# G32R502 register map
Vendor: Geehy Semiconductor Co., Ltd.; Series: G32R5; File version: 1.0
CPU: CM52 r0p1, little endian, MPU, FPU, DSP, VTOR, 4 interrupt priority bits
Registers are 32-bit, read-write, reset 0x0 unless marked. A register's access mark holds for its fields unless they carry their own. Offsets are from the block's base; [hi:lo] are bit positions; {n}, {i} and the like mark numbered series.

## ROM_PREFETCH
Base 0x40013C00
0x00 BOOT_ROM_PREFETCH
  [0] BOOT_ROM_PREFETCH — BOOT ROM prefetch function enable

## ROM_WAIT_STATE
Base 0x40013D00
0x00 BOOT_ROM_LATENCY reset 0x1 — BOOT ROM delay configuration register
  [2:0] BOOT_ROM_LATENCY — BOOT ROM delay configuration

## DEV — DEV_REGS
Base 0x40013100
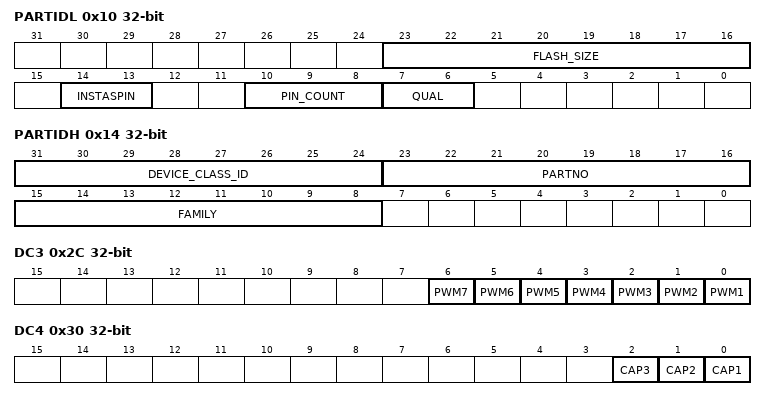
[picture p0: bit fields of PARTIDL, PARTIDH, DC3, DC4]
0x10 PARTIDL ro — Lower 32-bit of Device PART Identification Numble
  [23:16] FLASH_SIZE — Flash size in KB
  [14:13] INSTASPIN — Instaspin feature set
  [10:8] PIN_COUNT — Device Pin Count
  [7:6] QUAL — Qualification Status
0x14 PARTIDH ro — Upper 32-bit of Device PART Identification Numble
  [31:24] DEVICE_CLASS_ID
  [23:16] PARTNO — Device part number
  [15:8] FAMILY — Device family
0x18 REVID ro — Device Revision Number
  [15:0] REVID — Device Revision
0x2C DC3 ro — Device Capability Register
  [n-1] PWM{n} (n=1..7) — PWM{n} function
0x30 DC4 ro — Device Capability Register
  [2] CAP3 — CAP3 function
  [1] CAP2 — CAP2 function
  [0] CAP1 — CAP1 function
0x34 DC5 ro — Device Capability Register
  [0] QEP1 — QEP1 function
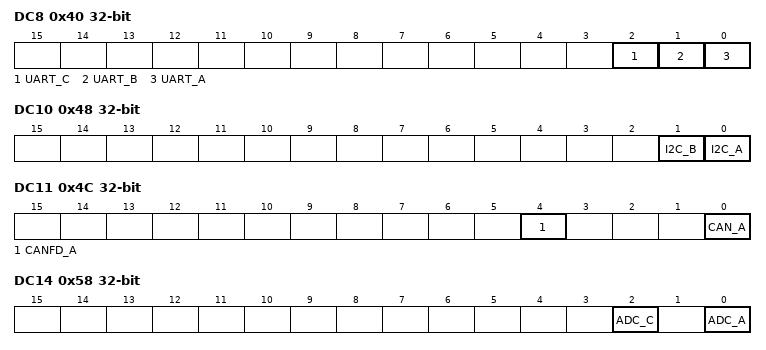
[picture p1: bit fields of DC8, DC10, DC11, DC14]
0x40 DC8 ro — Device Capability Register
  [2] UART_C — UARTC function
  [1] UART_B — UARTB function
  [0] UART_A — UARTA function
0x44 DC9 ro — Device Capability Register
  [0] SPI_A — SPIA function
0x48 DC10 ro — Device Capability Register
  [1] I2C_B — I2CB function
  [0] I2C_A — I2CA function
0x4C DC11 ro — Device Capability Register
  [4] CANFD_A — CANFDA function
  [0] CAN_A — CANA function
0x58 DC14 ro — Device Capability Register
  [2] ADC_C — ADCC function
  [0] ADC_A — ADCA function
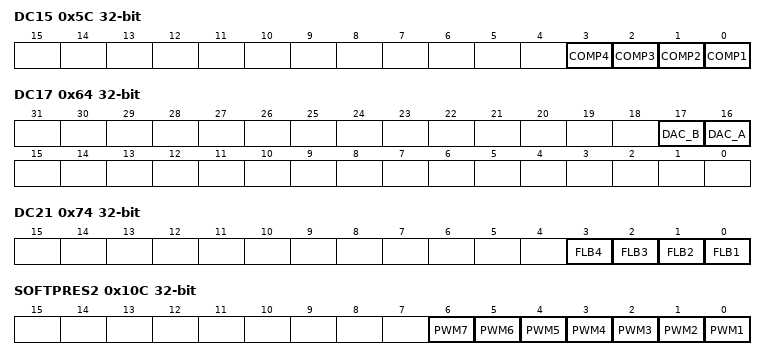
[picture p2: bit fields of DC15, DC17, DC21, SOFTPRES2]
0x5C DC15 ro — Device Capability Register
  [n-1] COMP{n} (n=1..4) — COMP{n} function
0x64 DC17 ro — Device Capability Register
  [17] DAC_B — DACB function
  [16] DAC_A — DACA function
0x74 DC21 ro — Device Capability Register
  [n-1] FLB{n} (n=1..4) — FLB{n} function
0x7C DC23 ro — Device Capability Register
  [0] LIN_A — LINA function
0x80 DC24 ro — Device Capability Register
  [0] PMBUS_A — PMBUSA function
0x84 DC25 ro — Device Capability Register
  [0] DCC_0 — DCC function
0x10C SOFTPRES2 — Peripheral Software Reset register
  [n-1] PWM{n} (n=1..7) — PWM{n} reset Configuration
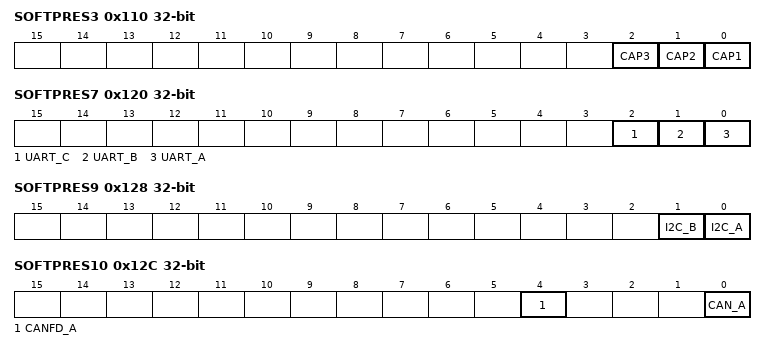
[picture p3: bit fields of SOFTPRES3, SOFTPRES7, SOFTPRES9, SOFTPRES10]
0x110 SOFTPRES3 — Peripheral Software Reset register
  [2] CAP3 — CAP3 reset Configuration
  [1] CAP2 — CAP2 reset Configuration
  [0] CAP1 — CAP1 reset Configuration
0x114 SOFTPRES4 — Peripheral Software Reset register
  [0] QEP1 — QEP1 reset Configuration
0x120 SOFTPRES7 — Peripheral Software Reset register
  [2] UART_C — UART_C reset Configuration
  [1] UART_B — UART_B reset Configuration
  [0] UART_A — UART_A reset Configuration
0x124 SOFTPRES8 — Peripheral Software Reset register
  [0] SPI_A — SPI_A reset Configuration
0x128 SOFTPRES9 — Peripheral Software Reset register
  [1] I2C_B — I2C_B reset Configuration
  [0] I2C_A — I2C_A reset Configuration
0x12C SOFTPRES10 — Peripheral Software Reset register
  [4] CANFD_A — CANFDA reset Configuration
  [0] CAN_A — CAN_A reset Configuration
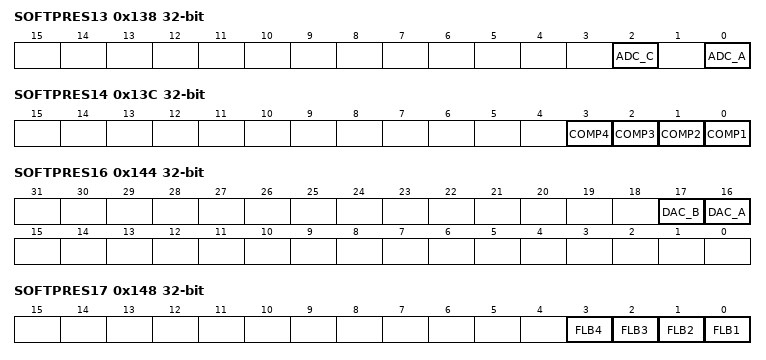
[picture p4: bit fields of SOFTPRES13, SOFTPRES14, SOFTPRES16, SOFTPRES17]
0x138 SOFTPRES13 — Peripheral Software Reset register
  [2] ADC_C — ADC_C reset Configuration
  [0] ADC_A — ADC_A reset Configuration
0x13C SOFTPRES14 — Peripheral Software Reset register
  [n-1] COMP{n} (n=1..4) — COMP{n} reset Configuration
0x144 SOFTPRES16 — Peripheral Software Reset register
  [17] DAC_B — DAC_B reset Configuration
  [16] DAC_A — DAC_A reset Configuration
0x148 SOFTPRES17 — Peripheral Software Reset register
  [n-1] FLB{n} (n=1..4) — FLB{n} reset Configuration
0x150 SOFTPRES19 — Peripheral Software Reset register
  [0] LIN_A — LIN_A reset Configuration
0x154 SOFTPRES20 — Peripheral Software Reset register
  [0] PMBUS_A — PMBUS_A reset Configuration
0x25C PACKSEL — Chip Footprint Select
  [3:0] PACKSEL — Chip Package Select
